AUTOSAR XML (schema 00048)
package /StartApplication/StartApplication_swc/DataTypes
  33 x impl type:
    EnumMEM_BlockStateType: compu {0=MEM_STATE_UNKNOWN, 1=MEM_STATE_WRITE_PENDING, 2=MEM_STATE_WRITE_FINISHED, 3=MEM_STATE_READ_PENDING, 4=MEM_STATE_READ_FINISHED, 5=MEM_STATE_WRITE_FAILED, 6=MEM_STATE_READ_FAILED}, range raw 0..6, implementation-data-type=uint8
    EnumNM_ApplStateType: compu {0=NM_APPL_STATE_FULL_COMM_EXTERN, 1=NM_APPL_STATE_FULL_COMM_INTERN, 2=NM_APPL_STATE_NO_COMM_EXTERN}, range raw 0..2, implementation-data-type=uint8
    NvM_ServiceIdType: compu {6=NVM_READ_BLOCK, 7=NVM_WRITE_BLOCK, 8=NVM_RESTORE_BLOCK_DEFAULTS, 9=NVM_ERASE_BLOCK, 11=NVM_INVALIDATE_NV_BLOCK, 12=NVM_READ_ALL}, range raw 0..12, implementation-data-type=uint8
    NvM_RequestResultType: compu {0=NVM_REQ_OK, 1=NVM_REQ_NOT_OK, 2=NVM_REQ_PENDING, 3=NVM_REQ_INTEGRITY_FAILED, 4=NVM_REQ_BLOCK_SKIPPED, 5=NVM_REQ_NV_INVALIDATED, 6=NVM_REQ_CANCELED, 7=NVM_REQ_REDUNDANCY_FAILED, 8=NVM_REQ_RESTORED_FROM_ROM}, range raw 0..8, implementation-data-type=uint8
    Dem_EventStatusType: compu {0=DEM_EVENT_STATUS_PASSED, 1=DEM_EVENT_STATUS_FAILED, 2=DEM_EVENT_STATUS_PREPASSED, 3=DEM_EVENT_STATUS_PREFAILED, 4=DEM_EVENT_STATUS_FDC_THRESHOLD_REACHED}, range raw 0..4, implementation-data-type=uint8
    Dem_OperationCycleStateType: compu {0=DEM_CYCLE_STATE_START, 1=DEM_CYCLE_STATE_END}, range raw 0..1, implementation-data-type=uint8
    Dcm_Data2ByteType: category=ARRAY, sw-calibration-access=READ-ONLY
      element Dcm_Data2ByteTypeElement: array-size=2, array-size-semantics=FIXED-SIZE, implementation-data-type=uint8
    Dcm_NegativeResponseCodeType:
      compu {0=DCM_E_POSITIVERESPONSE, 16=DCM_E_GENERALREJECT, 17=DCM_E_SERVICENOTSUPPORTED, 18=DCM_E_SUBFUNCTIONNOTSUPPORTED, 19=DCM_E_INCORRECTMESSAGELENGTHORINVALIDFORMAT, 20=DCM_E_RESPONSETOOLONG, 33=DCM_E_BUSYREPEATREQUEST, 34=DCM_E_CONDITIONSNOTCORRECT, 36=DCM_E_REQUESTSEQUENCEERROR, 37=DCM_E_NORESPONSEFROMSUBNETCOMPONENT, 38=DCM_E_FAILUREPREVENTSEXECUTIONOFREQUESTEDACTION, 49=DCM_E_REQUESTOUTOFRANGE, 51=DCM_E_SECURITYACCESSDENIED, 53=DCM_E_INVALIDKEY, 54=DCM_E_EXCEEDNUMBEROFATTEMPTS, 55=DCM_E_REQUIREDTIMEDELAYNOTEXPIRED, 112=DCM_E_UPLOADDOWNLOADNOTACCEPTED, 113=DCM_E_TRANSFERDATASUSPENDED, 114=DCM_E_GENERALPROGRAMMINGFAILURE, 115=DCM_E_WRONGBLOCKSEQUENCECOUNTER, 120=DCM_E_REQUESTCORRECTLYRECEIVEDRESPONSEPENDING, 126=DCM_E_SUBFUNCTIONNOTSUPPORTEDINACTIVESESSION, 127=DCM_E_SERVICENOTSUPPORTEDINACTIVESESSION, 129=DCM_E_RPMTOOHIGH, 130=DCM_E_RPMTOOLOW, 131=DCM_E_ENGINEISRUNNING, 132=DCM_E_ENGINEISNOTRUNNING, 133=DCM_E_ENGINERUNTIMETOOLOW, 134=DCM_E_TEMPERATURETOOHIGH, 135=DCM_E_TEMPERATURETOOLOW, 136=DCM_E_VEHICLESPEEDTOOHIGH, 137=DCM_E_VEHICLESPEEDTOOLOW, 138=DCM_E_THROTTLE_PEDALTOOHIGH, 139=DCM_E_THROTTLE_PEDALTOOLOW, 140=DCM_E_TRANSMISSIONRANGENOTINNEUTRAL, 141=DCM_E_TRANSMISSIONRANGENOTINGEAR, 143=DCM_E_BRAKESWITCH_NOTCLOSED, 144=DCM_E_SHIFTERLEVERNOTINPARK, 145=DCM_E_TORQUECONVERTERCLUTCHLOCKED, 146=DCM_E_VOLTAGETOOHIGH, 147=DCM_E_VOLTAGETOOLOW}
      range raw 0..147
      implementation-data-type=uint8
    DataArray_Type_2: category=ARRAY, sw-calibration-access=READ-ONLY
      element DataArray_Type_2Element: array-size=2, array-size-semantics=FIXED-SIZE, implementation-data-type=uint8
    WdgM_CheckpointIdType: implementation-data-type=uint16
    freshnessValueType: category=ARRAY, sw-calibration-access=READ-ONLY
      element freshnessValueTypeElement: array-size=8, array-size-semantics=FIXED-SIZE, implementation-data-type=uint8
    Csm_KeyDataType_StartApplication_CsmKey: category=ARRAY, sw-calibration-access=READ-ONLY
      element Csm_KeyDataType_StartApplication_CsmKeyElement: array-size=16, array-size-semantics=FIXED-SIZE, implementation-data-type=uint8
    ComM_ModeType: compu {0=COMM_NO_COMMUNICATION, 1=COMM_SILENT_COMMUNICATION, 2=COMM_FULL_COMMUNICATION}, range raw 0..3, implementation-data-type=uint8
    IdtUint8Array_508: category=ARRAY, sw-calibration-access=READ-ONLY
      element IdtUint8Array_508Element: array-size=508, array-size-semantics=FIXED-SIZE, implementation-data-type=uint8
    DtLargeDataControlCommunicationDataElementType: category=STRUCTURE
      element Value: implementation-data-type=IdtUint8Array_508
      element Length: implementation-data-type=uint16
    Csm_DecryptDataType_CsmPrimitives_AES_DecryptElement: category=ARRAY, sw-calibration-access=READ-ONLY
      element Csm_DecryptDataType_CsmPrimitives_AES_DecryptElementElement: array-size=1024, array-size-semantics=FIXED-SIZE, implementation-data-type=uint8
    Csm_DecryptResultType_CsmPrimitives_AES_DecryptElement: category=ARRAY, sw-calibration-access=READ-ONLY
      element Csm_DecryptResultType_CsmPrimitives_AES_DecryptElementElement: array-size=1024, array-size-semantics=FIXED-SIZE, implementation-data-type=uint8
    Csm_EncryptDataType_CsmPrimitives_AES_EncryptElement: category=ARRAY, sw-calibration-access=READ-ONLY
      element Csm_EncryptDataType_CsmPrimitives_AES_EncryptElementElement: array-size=1024, array-size-semantics=FIXED-SIZE, implementation-data-type=uint8
    Csm_EncryptResultType_CsmPrimitives_AES_EncryptElement: category=ARRAY, sw-calibration-access=READ-ONLY
      element Csm_EncryptResultType_CsmPrimitives_AES_EncryptElementElement: array-size=1024, array-size-semantics=FIXED-SIZE, implementation-data-type=uint8
    Csm_MacGenerateDataType_CsmPrimitives_MAC_GenerateElement: category=ARRAY, sw-calibration-access=READ-ONLY
      element Csm_MacGenerateDataType_CsmPrimitives_MAC_GenerateElementElement: array-size=1024, array-size-semantics=FIXED-SIZE, implementation-data-type=uint8
    Csm_MacGenerateResultType_CsmPrimitives_MAC_GenerateElement: category=ARRAY, sw-calibration-access=READ-ONLY
      element Csm_MacGenerateResultType_CsmPrimitives_MAC_GenerateElementElement: array-size=8, array-size-semantics=FIXED-SIZE, implementation-data-type=uint8
    Csm_MacVerifyDataType_CsmPrimitives_MAC_VerifyElement: category=ARRAY, sw-calibration-access=READ-ONLY
      element Csm_MacVerifyDataType_CsmPrimitives_MAC_VerifyElementElement: array-size=1024, array-size-semantics=FIXED-SIZE, implementation-data-type=uint8
    Csm_MacVerifyCompareType_CsmPrimitives_MAC_VerifyElement: category=ARRAY, sw-calibration-access=READ-ONLY
      element Csm_MacVerifyCompareType_CsmPrimitives_MAC_VerifyElementElement: array-size=1, array-size-semantics=FIXED-SIZE, implementation-data-type=uint8
    Crypto_VerifyResultType: compu {0=CRYPTO_E_VER_OK, 1=CRYPTO_E_VER_NOT_OK}, range raw 0..1, implementation-data-type=uint8
    Csm_KeyDataType_StartApplication_CsmKey_MAC: category=ARRAY, sw-calibration-access=READ-ONLY
      element Csm_KeyDataType_StartApplication_CsmKey_MACElement: array-size=16, array-size-semantics=FIXED-SIZE, implementation-data-type=uint8
    Csm_KeyDataType_StartApplication_CsmKey_Dec: category=ARRAY, sw-calibration-access=READ-ONLY
      element Csm_KeyDataType_StartApplication_CsmKey_DecElement: array-size=16, array-size-semantics=FIXED-SIZE, implementation-data-type=uint8
    Csm_KeyDataType_StartApplication_CsmKey_Enc: category=ARRAY, sw-calibration-access=READ-ONLY
      element Csm_KeyDataType_StartApplication_CsmKey_EncElement: array-size=16, array-size-semantics=FIXED-SIZE, implementation-data-type=uint8
    IdtLargeDataControlCommunicationInfo: category=STRUCTURE
      element Data: implementation-data-type=IdtUint8Array_508
      element Length: implementation-data-type=uint16
      element NewDataFlag: implementation-data-type=boolean
    DtInterCoreSlaveDataElementType: category=STRUCTURE
      element CoreID: implementation-data-type=uint8
      element DataValue: implementation-data-type=uint8
    EnumLastReceivedRxValueType: compu {0=STARTAPPLICATIONETH_LAST_RX_VALUE_CTRL, 1=STARTAPPLICATIONETH_LAST_RX_VALUE_DATA}, range raw 1, implementation-data-type=uint8
    DtEthernetCommunicationDataElementType: category=STRUCTURE
      element Value: implementation-data-type=IdtUint8Array_508
      element Length: implementation-data-type=uint16
    IdtEthernetCommunicationInfo: category=STRUCTURE
      element Data: implementation-data-type=IdtUint8Array_508
      element Length: implementation-data-type=uint16
      element NewDataFlag: implementation-data-type=boolean
    EnumActiveComponentType:
      compu {0=STARTAPPLICATION_ACTIVE_COMPONENT_COM_RXTX, 1=STARTAPPLICATION_ACTIVE_COMPONENT_MEM, 2=STARTAPPLICATION_ACTIVE_COMPONENT_DIAG, 3=STARTAPPLICATION_ACTIVE_COMPONENT_COM_TXONLY, 4=STARTAPPLICATION_ACTIVE_COMPONENT_WDG, 5=STARTAPPLICATION_ACTIVE_COMPONENT_XCP, 7=STARTAPPLICATION_ACTIVE_COMPONENT_MULTICORE, 9=STARTAPPLICATION_ACTIVE_COMPONENT_NM, 11=STARTAPPLICATION_ACTIVE_COMPONENT_ETH, 13=STARTAPPLICATION_ACTIVE_COMPONENT_SECURITY, 255=STARTAPPLICATION_ACTIVE_COMPONENT_INVALID}
      range raw 0..255
      implementation-data-type=uint8
package /StartApplication/StartApplication_swc/Interfaces
  5 x sender receiver interface:
    PiGeneric
      data DeGeneric: type=uint8
    PiSig_StartAppl_LinData_Tx_oFrame_LinTr_MyECU_oLIN00_d383dc6b_Tx
      data DeSig_StartAppl_LinData_Tx_oFrame_LinTr_MyECU_oLIN00_d383dc6b_Tx: type=uint8
    PiSignal_MyECU_SecOC_Rx1_omsg_SecOC_MyECU_Rx_oCAN_985386a6_Rx
      data DeSignal_MyECU_SecOC_Rx1_omsg_SecOC_MyECU_Rx_oCAN_985386a6_Rx: type=uint8
    PiSignal_MyECU_SecOC_Tx1_omsg_SecOC_MyECU_Tx_oCAN_fe3fbdd2_Tx
      data DeSignal_MyECU_SecOC_Tx1_omsg_SecOC_MyECU_Tx_oCAN_fe3fbdd2_Tx: type=uint8
    PiSig_StartAppl_LinData_Rx_oFrame_LinTr_Slave1_oLIN00_149fe319_Rx
      data DeSig_StartAppl_LinData_Rx_oFrame_LinTr_Slave1_oLIN00_149fe319_Rx: type=uint8
  15 x client server interface, all with is-service=true, service-kind=VENDOR-SPECIFIC:
    PiUR_CN_LIN00_0a7bdc9c
      4 x operation:
        GetCurrentComMode: possible-error=PiUR_CN_LIN00_0a7bdc9c/E_NOT_OK
          arg ComMode: type=ComM_ModeType, direction=OUT
        GetMaxComMode: possible-error=PiUR_CN_LIN00_0a7bdc9c/E_NOT_OK
          arg ComMode: type=ComM_ModeType, direction=OUT
        GetRequestedComMode: possible-error=PiUR_CN_LIN00_0a7bdc9c/E_NOT_OK
          arg ComMode: type=ComM_ModeType, direction=OUT
        RequestComMode: possible-error=[PiUR_CN_LIN00_0a7bdc9c/E_NOT_OK, PiUR_CN_LIN00_0a7bdc9c/E_MODE_LIMITATION]
          arg ComMode: type=ComM_ModeType, direction=IN
      error E_NOT_OK: error-code=1
      error E_MODE_LIMITATION: error-code=2
    PiUR_CN_CAN_52ce3533
      4 x operation:
        GetCurrentComMode: possible-error=PiUR_CN_CAN_52ce3533/E_NOT_OK
          arg ComMode: type=ComM_ModeType, direction=OUT
        GetMaxComMode: possible-error=PiUR_CN_CAN_52ce3533/E_NOT_OK
          arg ComMode: type=ComM_ModeType, direction=OUT
        GetRequestedComMode: possible-error=PiUR_CN_CAN_52ce3533/E_NOT_OK
          arg ComMode: type=ComM_ModeType, direction=OUT
        RequestComMode: possible-error=[PiUR_CN_CAN_52ce3533/E_NOT_OK, PiUR_CN_CAN_52ce3533/E_MODE_LIMITATION]
          arg ComMode: type=ComM_ModeType, direction=IN
      error E_NOT_OK: error-code=1
      error E_MODE_LIMITATION: error-code=2
    PiUR_MyECU_EEI_V10_NM_507fc7ae
      4 x operation:
        GetCurrentComMode: possible-error=PiUR_MyECU_EEI_V10_NM_507fc7ae/E_NOT_OK
          arg ComMode: type=ComM_ModeType, direction=OUT
        GetMaxComMode: possible-error=PiUR_MyECU_EEI_V10_NM_507fc7ae/E_NOT_OK
          arg ComMode: type=ComM_ModeType, direction=OUT
        GetRequestedComMode: possible-error=PiUR_MyECU_EEI_V10_NM_507fc7ae/E_NOT_OK
          arg ComMode: type=ComM_ModeType, direction=OUT
        RequestComMode: possible-error=[PiUR_MyECU_EEI_V10_NM_507fc7ae/E_NOT_OK, PiUR_MyECU_EEI_V10_NM_507fc7ae/E_MODE_LIMITATION]
          arg ComMode: type=ComM_ModeType, direction=IN
      error E_NOT_OK: error-code=1
      error E_MODE_LIMITATION: error-code=2
    PiUR_MyECU_EEI_U_2cc5e3dc
      4 x operation:
        GetCurrentComMode: possible-error=PiUR_MyECU_EEI_U_2cc5e3dc/E_NOT_OK
          arg ComMode: type=ComM_ModeType, direction=OUT
        GetMaxComMode: possible-error=PiUR_MyECU_EEI_U_2cc5e3dc/E_NOT_OK
          arg ComMode: type=ComM_ModeType, direction=OUT
        GetRequestedComMode: possible-error=PiUR_MyECU_EEI_U_2cc5e3dc/E_NOT_OK
          arg ComMode: type=ComM_ModeType, direction=OUT
        RequestComMode: possible-error=[PiUR_MyECU_EEI_U_2cc5e3dc/E_NOT_OK, PiUR_MyECU_EEI_U_2cc5e3dc/E_MODE_LIMITATION]
          arg ComMode: type=ComM_ModeType, direction=IN
      error E_NOT_OK: error-code=1
      error E_MODE_LIMITATION: error-code=2
    PiPS_StartApplication_NvMBlock1
      operation WriteBlock: possible-error=PiPS_StartApplication_NvMBlock1/E_NOT_OK
        arg SrcPtr: type=dtRef_const_VOID, direction=IN
      operation ReadBlock: possible-error=PiPS_StartApplication_NvMBlock1/E_NOT_OK
        arg DstPtr: type=dtRef_VOID, direction=IN
      error E_NOT_OK: error-code=1
    PiNvM_RpNotifyJobEnd_StartApplication_NvMBlock1
      operation JobFinished
        arg ServiceId: type=NvM_ServiceIdType, direction=IN
        arg JobResult: type=NvM_RequestResultType, direction=IN
    PiPS_StartApplication_NvMBlock2
      operation WriteBlock: possible-error=PiPS_StartApplication_NvMBlock2/E_NOT_OK
        arg SrcPtr: type=dtRef_const_VOID, direction=IN
      operation ReadBlock: possible-error=PiPS_StartApplication_NvMBlock2/E_NOT_OK
        arg DstPtr: type=dtRef_VOID, direction=IN
      error E_NOT_OK: error-code=1
    PiNvM_RpNotifyJobEnd_StartApplication_NvMBlock2
      operation JobFinished
        arg ServiceId: type=NvM_ServiceIdType, direction=IN
        arg JobResult: type=NvM_RequestResultType, direction=IN
    PiDiagnosticMonitor_DEM_EVENT_StartApplication
      operation SetEventStatus: possible-error=PiDiagnosticMonitor_DEM_EVENT_StartApplication/E_NOT_OK
        arg EventStatus: type=Dem_EventStatusType, direction=IN
      operation ResetEventStatus: possible-error=PiDiagnosticMonitor_DEM_EVENT_StartApplication/E_NOT_OK
      error E_NOT_OK: error-code=1
    PiDemOpCycle_PowerCycle
      operation SetOperationCycleState: possible-error=PiDemOpCycle_PowerCycle/E_NOT_OK
        arg CycleState: type=Dem_OperationCycleStateType, direction=IN
      error E_NOT_OK: error-code=1
    PiDcmDataService_DID_StartApplication
      operation WriteData
        arg Data: type=Dcm_Data2ByteType, direction=IN
        arg ErrorCode: type=Dcm_NegativeResponseCodeType, direction=OUT
      operation ReadData
        arg Data: type=Dcm_Data2ByteType, direction=OUT
      operation ConditionCheckRead
        arg ErrorCode: type=Dcm_NegativeResponseCodeType, direction=OUT
    PiDemDataService_DemDataElementClass_StartApplication
      operation ReadData
        arg Data: type=DataArray_Type_2, direction=OUT
    PiAliveWdgMSupervisedEntity_StartApplication
      operation CheckpointReached: possible-error=PiAliveWdgMSupervisedEntity_StartApplication/E_NOT_OK
        arg checkpointId: type=WdgM_CheckpointIdType, direction=IN
      error E_NOT_OK: error-code=1
    PiCsmKeyManagement_StartApplication_CsmKey
      operation KeyElementSet: possible-error=[PiCsmKeyManagement_StartApplication_CsmKey/E_NOT_OK, PiCsmKeyManagement_StartApplication_CsmKey/CSM_E_BUSY, PiCsmKeyManagement_StartApplication_CsmKey/CSM_E_SMALL_BUFFER, PiCsmKeyManagement_StartApplication_CsmKey/CSM_E_KEY_WRITE_FAIL, PiCsmKeyManagement_StartApplication_CsmKey/CSM_E_KEY_NOT_AVAILABLE, PiCsmKeyManagement_StartApplication_CsmKey/CSM_E_KEY_SIZE_MISMATCH]
        arg keyElementId: type=uint32, direction=IN
        arg keyPtr: type=Csm_KeyDataType_StartApplication_CsmKey, direction=IN, server-argument-impl-policy=USE-ARRAY-BASE-TYPE
        arg keyLength: type=uint32, direction=IN
      operation KeySetValid: possible-error=[PiCsmKeyManagement_StartApplication_CsmKey/E_NOT_OK, PiCsmKeyManagement_StartApplication_CsmKey/CSM_E_BUSY]
      6 x error:
        E_NOT_OK: error-code=1
        CSM_E_BUSY: error-code=2
        CSM_E_SMALL_BUFFER: error-code=3
        CSM_E_KEY_WRITE_FAIL: error-code=7
        CSM_E_KEY_NOT_AVAILABLE: error-code=8
        CSM_E_KEY_SIZE_MISMATCH: error-code=10
    PiFreshnessManagement
      operation GetRxFreshness: possible-error=[E_OK, PiFreshnessManagement/E_NOT_OK, E_BUSY]
        6 x arg:
          freshnessValueId: type=uint16, direction=IN
          truncatedFreshnessValue: type=freshnessValueType, direction=IN
          truncatedFreshnessValueLength: type=uint32, direction=IN
          authVerifyAttempts: type=uint16, direction=IN
          freshnessValue: type=freshnessValueType, direction=OUT
          freshnessValueLength: type=uint32, direction=INOUT
      operation GetTxFreshness: possible-error=[E_OK, PiFreshnessManagement/E_NOT_OK, E_BUSY]
        arg freshnessValueId: type=uint16, direction=IN
        arg freshnessValue: type=freshnessValueType, direction=OUT
        arg freshnessValueLength: type=uint32, direction=INOUT
      error E_OK: error-code=0
      error E_NOT_OK: error-code=1
      error E_BUSY: error-code=2
  sender receiver interface PiLargeDataControlCommunication
    data DeLargeDataControlCommunication: sw-impl-policy=QUEUED, type=DtLargeDataControlCommunicationDataElementType
  7 x client server interface, all with is-service=true, service-kind=VENDOR-SPECIFIC:
    PiStartApplication_ECB_AES_Decrypt
      operation Decrypt: possible-error=[PiStartApplication_ECB_AES_Decrypt/E_NOT_OK, PiStartApplication_ECB_AES_Decrypt/CSM_E_BUSY, PiStartApplication_ECB_AES_Decrypt/CSM_E_SMALL_BUFFER, PiStartApplication_ECB_AES_Decrypt/CSM_E_KEY_NOT_VALID, PiStartApplication_ECB_AES_Decrypt/CSM_E_KEY_SIZE_MISMATCH, PiStartApplication_ECB_AES_Decrypt/CSM_E_KEY_EMPTY]
        4 x arg:
          dataBuffer: type=Csm_DecryptDataType_CsmPrimitives_AES_DecryptElement, direction=IN
          dataLength: type=uint32, direction=IN
          resultBuffer: type=Csm_DecryptResultType_CsmPrimitives_AES_DecryptElement, direction=OUT
          resultLength: type=uint32, direction=INOUT
      6 x error:
        E_NOT_OK: error-code=1
        CSM_E_BUSY: error-code=2
        CSM_E_SMALL_BUFFER: error-code=3
        CSM_E_KEY_NOT_VALID: error-code=9
        CSM_E_KEY_SIZE_MISMATCH: error-code=10
        CSM_E_KEY_EMPTY: error-code=13
    PiStartApplication_ECB_AES_Encrypt
      operation Encrypt: possible-error=[PiStartApplication_ECB_AES_Encrypt/E_NOT_OK, PiStartApplication_ECB_AES_Encrypt/CSM_E_BUSY, PiStartApplication_ECB_AES_Encrypt/CSM_E_SMALL_BUFFER, PiStartApplication_ECB_AES_Encrypt/CSM_E_KEY_NOT_VALID, PiStartApplication_ECB_AES_Encrypt/CSM_E_KEY_SIZE_MISMATCH, PiStartApplication_ECB_AES_Encrypt/CSM_E_KEY_EMPTY]
        4 x arg:
          dataBuffer: type=Csm_EncryptDataType_CsmPrimitives_AES_EncryptElement, direction=IN
          dataLength: type=uint32, direction=IN
          resultBuffer: type=Csm_EncryptResultType_CsmPrimitives_AES_EncryptElement, direction=OUT
          resultLength: type=uint32, direction=INOUT
      6 x error:
        E_NOT_OK: error-code=1
        CSM_E_BUSY: error-code=2
        CSM_E_SMALL_BUFFER: error-code=3
        CSM_E_KEY_NOT_VALID: error-code=9
        CSM_E_KEY_SIZE_MISMATCH: error-code=10
        CSM_E_KEY_EMPTY: error-code=13
    PiStartApplication_MAC_Generate
      operation MacGenerate: possible-error=[PiStartApplication_MAC_Generate/E_NOT_OK, PiStartApplication_MAC_Generate/CSM_E_BUSY, PiStartApplication_MAC_Generate/CSM_E_SMALL_BUFFER]
        4 x arg:
          dataBuffer: type=Csm_MacGenerateDataType_CsmPrimitives_MAC_GenerateElement, direction=IN
          dataLength: type=uint32, direction=IN
          resultBuffer: type=Csm_MacGenerateResultType_CsmPrimitives_MAC_GenerateElement, direction=OUT
          resultLength: type=uint32, direction=INOUT
      error E_NOT_OK: error-code=1
      error CSM_E_BUSY: error-code=2
      error CSM_E_SMALL_BUFFER: error-code=3
    PiStartApplication_MAC_Verify
      operation MacVerify: possible-error=[PiStartApplication_MAC_Verify/E_NOT_OK, PiStartApplication_MAC_Verify/CSM_E_BUSY, PiStartApplication_MAC_Verify/CSM_E_SMALL_BUFFER]
        5 x arg:
          dataBuffer: type=Csm_MacVerifyDataType_CsmPrimitives_MAC_VerifyElement, direction=IN
          dataLength: type=uint32, direction=IN
          compareBuffer: type=Csm_MacVerifyCompareType_CsmPrimitives_MAC_VerifyElement, direction=IN
          compareLength: type=uint32, direction=IN
          verifyResult: type=Crypto_VerifyResultType, direction=OUT
      error E_NOT_OK: error-code=1
      error CSM_E_BUSY: error-code=2
      error CSM_E_SMALL_BUFFER: error-code=3
    PiStartApplication_CsmKey_MAC
      operation KeySetValid: possible-error=[PiStartApplication_CsmKey_MAC/E_NOT_OK, PiStartApplication_CsmKey_MAC/CSM_E_BUSY]
      operation KeyElementSet: possible-error=[PiStartApplication_CsmKey_MAC/E_NOT_OK, PiStartApplication_CsmKey_MAC/CSM_E_BUSY, PiStartApplication_CsmKey_MAC/CSM_E_KEY_WRITE_FAIL, PiStartApplication_CsmKey_MAC/CSM_E_KEY_NOT_AVAILABLE, PiStartApplication_CsmKey_MAC/CSM_E_KEY_SIZE_MISMATCH]
        arg keyElementId: type=uint32, direction=IN
        arg keyPtr: type=Csm_KeyDataType_StartApplication_CsmKey_MAC, direction=IN
        arg keyLength: type=uint32, direction=IN
      operation KeyElementGet: possible-error=[PiStartApplication_CsmKey_MAC/E_NOT_OK, PiStartApplication_CsmKey_MAC/CSM_E_BUSY, PiStartApplication_CsmKey_MAC/CSM_E_SMALL_BUFFER, PiStartApplication_CsmKey_MAC/CSM_E_KEY_READ_FAIL, PiStartApplication_CsmKey_MAC/CSM_E_KEY_NOT_AVAILABLE, PiStartApplication_CsmKey_MAC/CSM_E_KEY_EMPTY]
        arg keyElementId: type=uint32, direction=IN
        arg keyPtr: type=Csm_KeyDataType_StartApplication_CsmKey_MAC, direction=OUT
        arg keyLength: type=uint32, direction=OUT
      8 x error:
        E_NOT_OK: error-code=1
        CSM_E_BUSY: error-code=2
        CSM_E_KEY_WRITE_FAIL: error-code=7
        CSM_E_KEY_NOT_AVAILABLE: error-code=8
        CSM_E_KEY_SIZE_MISMATCH: error-code=10
        CSM_E_SMALL_BUFFER: error-code=3
        CSM_E_KEY_READ_FAIL: error-code=6
        CSM_E_KEY_EMPTY: error-code=13
    PiStartApplication_CsmKey_Dec
      operation KeySetValid: possible-error=[PiStartApplication_CsmKey_Dec/E_NOT_OK, PiStartApplication_CsmKey_Dec/CSM_E_BUSY]
      operation KeyElementSet: possible-error=[PiStartApplication_CsmKey_Dec/E_NOT_OK, PiStartApplication_CsmKey_Dec/CSM_E_BUSY, PiStartApplication_CsmKey_Dec/CSM_E_KEY_WRITE_FAIL, PiStartApplication_CsmKey_Dec/CSM_E_KEY_NOT_AVAILABLE, PiStartApplication_CsmKey_Dec/CSM_E_KEY_SIZE_MISMATCH]
        arg keyElementId: type=uint32, direction=IN
        arg keyPtr: type=Csm_KeyDataType_StartApplication_CsmKey_Dec, direction=IN
        arg keyLength: type=uint32, direction=IN
      operation KeyElementGet: possible-error=[PiStartApplication_CsmKey_Dec/E_NOT_OK, PiStartApplication_CsmKey_Dec/CSM_E_BUSY, PiStartApplication_CsmKey_Dec/CSM_E_SMALL_BUFFER, PiStartApplication_CsmKey_Dec/CSM_E_KEY_READ_FAIL, PiStartApplication_CsmKey_Dec/CSM_E_KEY_NOT_AVAILABLE]
        arg keyElementId: type=uint32, direction=IN
        arg keyPtr: type=Csm_KeyDataType_StartApplication_CsmKey_Dec, direction=OUT
        arg keyLength: type=uint32, direction=OUT
      7 x error:
        E_NOT_OK: error-code=1
        CSM_E_BUSY: error-code=2
        CSM_E_KEY_WRITE_FAIL: error-code=7
        CSM_E_KEY_NOT_AVAILABLE: error-code=8
        CSM_E_KEY_SIZE_MISMATCH: error-code=10
        CSM_E_SMALL_BUFFER: error-code=3
        CSM_E_KEY_READ_FAIL: error-code=6
    PiStartApplication_CsmKey_Enc
      operation KeySetValid: possible-error=[PiStartApplication_CsmKey_Enc/E_NOT_OK, PiStartApplication_CsmKey_Enc/CSM_E_BUSY]
      operation KeyElementSet: possible-error=[PiStartApplication_CsmKey_Enc/E_NOT_OK, PiStartApplication_CsmKey_Enc/CSM_E_BUSY, PiStartApplication_CsmKey_Enc/CSM_E_KEY_WRITE_FAIL, PiStartApplication_CsmKey_Enc/CSM_E_KEY_NOT_AVAILABLE, PiStartApplication_CsmKey_Enc/CSM_E_KEY_SIZE_MISMATCH]
        arg keyElementId: type=uint32, direction=IN
        arg keyPtr: type=Csm_KeyDataType_StartApplication_CsmKey_Enc, direction=IN
        arg keyLength: type=uint32, direction=IN
      operation KeyElementGet: possible-error=[PiStartApplication_CsmKey_Enc/E_NOT_OK, PiStartApplication_CsmKey_Enc/CSM_E_BUSY, PiStartApplication_CsmKey_Enc/CSM_E_SMALL_BUFFER, PiStartApplication_CsmKey_Enc/CSM_E_KEY_READ_FAIL, PiStartApplication_CsmKey_Enc/CSM_E_KEY_NOT_AVAILABLE, PiStartApplication_CsmKey_Enc/CSM_E_KEY_EMPTY]
        arg keyElementId: type=uint32, direction=IN
        arg keyPtr: type=Csm_KeyDataType_StartApplication_CsmKey_Enc, direction=OUT
        arg keyLength: type=uint32, direction=OUT
      8 x error:
        E_NOT_OK: error-code=1
        CSM_E_BUSY: error-code=2
        CSM_E_KEY_WRITE_FAIL: error-code=7
        CSM_E_KEY_NOT_AVAILABLE: error-code=8
        CSM_E_KEY_SIZE_MISMATCH: error-code=10
        CSM_E_SMALL_BUFFER: error-code=3
        CSM_E_KEY_READ_FAIL: error-code=6
        CSM_E_KEY_EMPTY: error-code=13
  5 x sender receiver interface:
    PiSignal_StartAppl_TxData_MyECU_omsg_StartAppl_Tx_MyECU_oCAN_8c58228b_Tx
      data DeSignal_StartAppl_TxData_MyECU_omsg_StartAppl_Tx_MyECU_oCAN_8c58228b_Tx: type=uint8
    PiSignal_StartAppl_RxData_MyECU_omsg_StartAppl_Rx_MyECU_oCAN_315f9453_Rx
      data DeSignal_StartAppl_RxData_MyECU_omsg_StartAppl_Rx_MyECU_oCAN_315f9453_Rx: type=uint8
    PiStartApplication_InterCoreMaster
      data DeInterCoreMaster: type=uint8
    PiStartApplication_InterCoreSlave
      data DeInterCoreSlave: type=DtInterCoreSlaveDataElementType
    PiEthernetCommunication
      data DeEthernetCommunication: sw-impl-policy=QUEUED, type=DtEthernetCommunicationDataElementType
package /StartApplication/StartApplication_swc/ComponentTypes
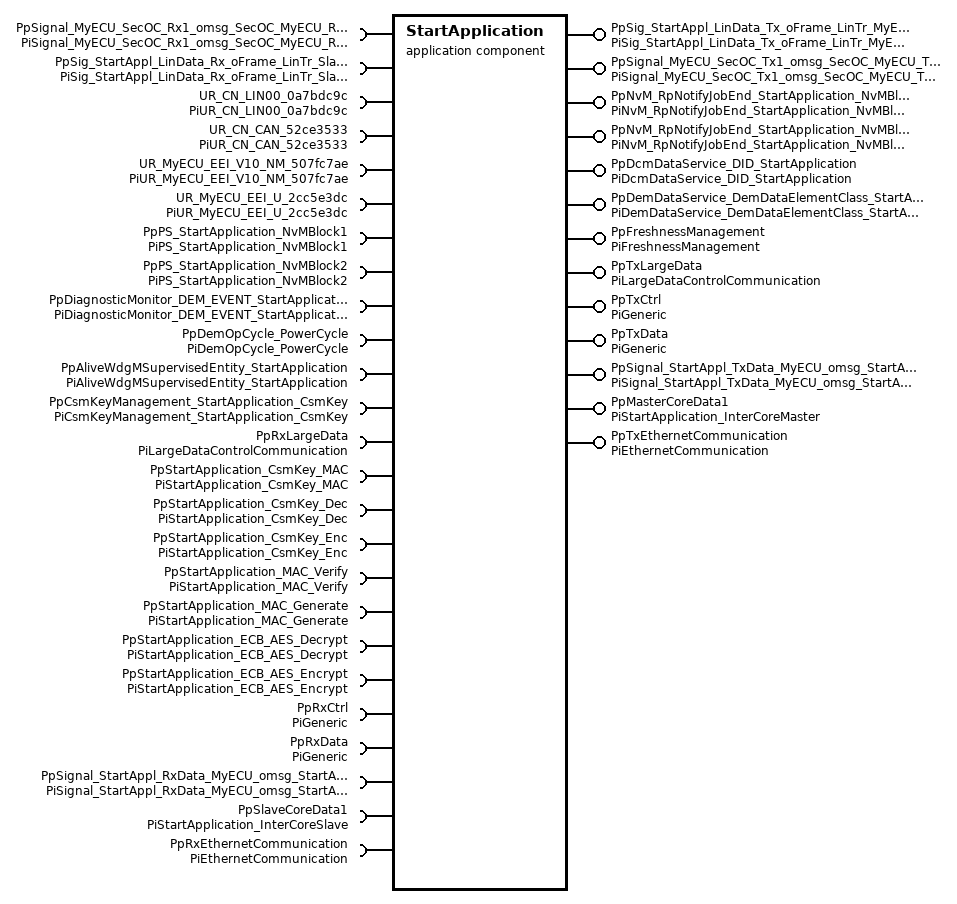
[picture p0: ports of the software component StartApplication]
  application sw component type StartApplication
    provide port PpSig_StartAppl_LinData_Tx_oFrame_LinTr_MyECU_oLIN00_d383dc6b_Tx: nonqueued-sender-com-spec{data-element=DeSig_StartAppl_LinData_Tx_oFrame_LinTr_MyECU_oLIN00_d383dc6b_Tx, init-value=0}, provided-interface=PiSig_StartAppl_LinData_Tx_oFrame_LinTr_MyECU_oLIN00_d383dc6b_Tx
    require port PpSignal_MyECU_SecOC_Rx1_omsg_SecOC_MyECU_Rx_oCAN_985386a6_Rx: nonqueued-receiver-com-spec{data-element=DeSignal_MyECU_SecOC_Rx1_omsg_SecOC_MyECU_Rx_oCAN_985386a6_Rx, handle-out-of-range-status=SILENT, init-value=0}, required-interface=PiSignal_MyECU_SecOC_Rx1_omsg_SecOC_MyECU_Rx_oCAN_985386a6_Rx
    provide port PpSignal_MyECU_SecOC_Tx1_omsg_SecOC_MyECU_Tx_oCAN_fe3fbdd2_Tx: nonqueued-sender-com-spec{data-element=DeSignal_MyECU_SecOC_Tx1_omsg_SecOC_MyECU_Tx_oCAN_fe3fbdd2_Tx, init-value=0}, provided-interface=PiSignal_MyECU_SecOC_Tx1_omsg_SecOC_MyECU_Tx_oCAN_fe3fbdd2_Tx
    5 x require port:
      PpSig_StartAppl_LinData_Rx_oFrame_LinTr_Slave1_oLIN00_149fe319_Rx: nonqueued-receiver-com-spec{data-element=DeSig_StartAppl_LinData_Rx_oFrame_LinTr_Slave1_oLIN00_149fe319_Rx, handle-out-of-range-status=SILENT, init-value=0}, required-interface=PiSig_StartAppl_LinData_Rx_oFrame_LinTr_Slave1_oLIN00_149fe319_Rx
      UR_CN_LIN00_0a7bdc9c: required-interface=PiUR_CN_LIN00_0a7bdc9c
      UR_CN_CAN_52ce3533: required-interface=PiUR_CN_CAN_52ce3533
      UR_MyECU_EEI_V10_NM_507fc7ae: required-interface=PiUR_MyECU_EEI_V10_NM_507fc7ae
      UR_MyECU_EEI_U_2cc5e3dc: required-interface=PiUR_MyECU_EEI_U_2cc5e3dc
    provide port PpNvM_RpNotifyJobEnd_StartApplication_NvMBlock1: provided-interface=PiNvM_RpNotifyJobEnd_StartApplication_NvMBlock1
    require port PpPS_StartApplication_NvMBlock1: required-interface=PiPS_StartApplication_NvMBlock1
    provide port PpNvM_RpNotifyJobEnd_StartApplication_NvMBlock2: provided-interface=PiNvM_RpNotifyJobEnd_StartApplication_NvMBlock2
    require port PpPS_StartApplication_NvMBlock2: required-interface=PiPS_StartApplication_NvMBlock2
    require port PpDiagnosticMonitor_DEM_EVENT_StartApplication: required-interface=PiDiagnosticMonitor_DEM_EVENT_StartApplication
    require port PpDemOpCycle_PowerCycle: required-interface=PiDemOpCycle_PowerCycle
    provide port PpDcmDataService_DID_StartApplication: provided-interface=PiDcmDataService_DID_StartApplication
    provide port PpDemDataService_DemDataElementClass_StartApplication: provided-interface=PiDemDataService_DemDataElementClass_StartApplication
    require port PpAliveWdgMSupervisedEntity_StartApplication: required-interface=PiAliveWdgMSupervisedEntity_StartApplication
    require port PpCsmKeyManagement_StartApplication_CsmKey: required-interface=PiCsmKeyManagement_StartApplication_CsmKey
    provide port PpFreshnessManagement: provided-interface=PiFreshnessManagement
    require port PpRxLargeData: nonqueued-receiver-com-spec{data-element=DeLargeDataControlCommunication, handle-out-of-range-status=SILENT}, required-interface=PiLargeDataControlCommunication
    provide port PpTxLargeData: nonqueued-sender-com-spec=DeLargeDataControlCommunication, provided-interface=PiLargeDataControlCommunication
    7 x require port:
      PpStartApplication_CsmKey_MAC: required-interface=PiStartApplication_CsmKey_MAC
      PpStartApplication_CsmKey_Dec: required-interface=PiStartApplication_CsmKey_Dec
      PpStartApplication_CsmKey_Enc: required-interface=PiStartApplication_CsmKey_Enc
      PpStartApplication_MAC_Verify: required-interface=PiStartApplication_MAC_Verify
      PpStartApplication_MAC_Generate: required-interface=PiStartApplication_MAC_Generate
      PpStartApplication_ECB_AES_Decrypt: required-interface=PiStartApplication_ECB_AES_Decrypt
      PpStartApplication_ECB_AES_Encrypt: required-interface=PiStartApplication_ECB_AES_Encrypt
    provide port PpTxCtrl: nonqueued-sender-com-spec{data-element=DeGeneric, init-value=0}, provided-interface=PiGeneric
    provide port PpTxData: nonqueued-sender-com-spec{data-element=DeGeneric, init-value=0}, provided-interface=PiGeneric
    require port PpRxCtrl: nonqueued-receiver-com-spec{data-element=DeGeneric, handle-out-of-range-status=SILENT, init-value=0}, required-interface=PiGeneric
    require port PpRxData: nonqueued-receiver-com-spec{data-element=DeGeneric, handle-out-of-range-status=SILENT, init-value=0}, required-interface=PiGeneric
    provide port PpSignal_StartAppl_TxData_MyECU_omsg_StartAppl_Tx_MyECU_oCAN_8c58228b_Tx: nonqueued-sender-com-spec{data-element=DeSignal_StartAppl_TxData_MyECU_omsg_StartAppl_Tx_MyECU_oCAN_8c58228b_Tx, init-value=0}, provided-interface=PiSignal_StartAppl_TxData_MyECU_omsg_StartAppl_Tx_MyECU_oCAN_8c58228b_Tx
    require port PpSignal_StartAppl_RxData_MyECU_omsg_StartAppl_Rx_MyECU_oCAN_315f9453_Rx: nonqueued-receiver-com-spec{data-element=DeSignal_StartAppl_RxData_MyECU_omsg_StartAppl_Rx_MyECU_oCAN_315f9453_Rx, handle-out-of-range-status=SILENT, init-value=0}, required-interface=PiSignal_StartAppl_RxData_MyECU_omsg_StartAppl_Rx_MyECU_oCAN_315f9453_Rx
    provide port PpMasterCoreData1: nonqueued-sender-com-spec{data-element=DeInterCoreMaster, init-value=0}, provided-interface=PiStartApplication_InterCoreMaster
    require port PpSlaveCoreData1: nonqueued-receiver-com-spec{data-element=DeInterCoreSlave, handle-out-of-range-status=SILENT, init-value=fields=[0, 0]}, required-interface=PiStartApplication_InterCoreSlave
    require port PpRxEthernetCommunication: nonqueued-receiver-com-spec{data-element=DeEthernetCommunication, handle-out-of-range-status=SILENT}, required-interface=PiEthernetCommunication
    provide port PpTxEthernetCommunication: nonqueued-sender-com-spec=DeEthernetCommunication, provided-interface=PiEthernetCommunication
    behavior StartApplicationInternalBehavior: handle-termination-and-restart=NO-SUPPORT
      ar-typed-per-instance-memorys:
        27 x data:
          Uptime: type=uint8
          TxCtrlSigValue: type=uint8
          TxDataSigValue: type=uint8
          SecOCTxFreshnessValue0: type=uint8
          COM_RxSigValue0: type=uint8
          COM_TxSigValue0: type=uint8
          COM_RxSigValue1: type=uint8
          COM_TxSigValue1: type=uint8
          COM_RxSigValue2: type=uint8
          COM_TxSigValue2: type=uint8
          MEM_ActiveBlock: type=uint8
          MEM_DataBuffer1: type=uint8
          MEM_DataBuffer2: type=uint8
          MEM_BlockState1: type=EnumMEM_BlockStateType
          MEM_BlockState2: type=EnumMEM_BlockStateType
          DIAG_LastRxData: type=uint8
          NM_ApplState: type=EnumNM_ApplStateType
          NM_ActiveChannelHasFullComRequest: type=uint8
          NM_BusSleepModeTimer: type=uint8
          NM_ActiveComMChannel: type=uint8
          NM_ActiveComMUsers: type=uint32
          WDG_AliveCycle: type=uint8
          WDG_AliveTimer: type=uint8
          XcpPimUpload: sw-calibration-access=READ-WRITE, type=uint16
          XcpPimDownload: sw-calibration-access=READ-WRITE, type=uint16
          ActiveComponent: type=EnumActiveComponentType
          COM_RxDataControlCommunicationBuffer: type=uint8
      4 x timing event:
        Timer_StartApplication_Cyclic1ms: start-on-event=StartApplication_Cyclic1ms, period=0.001
        Timer_StartApplication_Cyclic10ms: start-on-event=StartApplication_Cyclic10ms, period=0.01
        Timer_StartApplication_Cyclic250ms: start-on-event=StartApplication_Cyclic250ms, period=0.25
        Timer_StartApplication_Cyclic1000ms: start-on-event=StartApplication_Cyclic1000ms, period=1
      init event Timer_StartApplication_Init: start-on-event=StartApplication_Init
      8 x operation invoked event:
        OpEventStartApplication_MEM_JobFinished_StartApplication_NvMBlock1_JobFinished_PpNvM_RpNotifyJobEnd_StartApplication_NvMBlock1: start-on-event=StartApplication_MEM_JobFinished_StartApplication_NvMBlock1, operation=PpNvM_RpNotifyJobEnd_StartApplication_NvMBlock1.JobFinished
        OpEventStartApplication_MEM_JobFinished_StartApplication_NvMBlock2_JobFinished_PpNvM_RpNotifyJobEnd_StartApplication_NvMBlock2: start-on-event=StartApplication_MEM_JobFinished_StartApplication_NvMBlock2, operation=PpNvM_RpNotifyJobEnd_StartApplication_NvMBlock2.JobFinished
        OpEventStartApplication_DIAG_DcmReadData_ReadData_PpDcmDataService_DID_StartApplication: start-on-event=StartApplication_DIAG_DcmReadData, operation=PpDcmDataService_DID_StartApplication.ReadData
        OpEventStartApplication_DIAG_DcmWriteData_WriteData_PpDcmDataService_DID_StartApplication: start-on-event=StartApplication_DIAG_DcmWriteData, operation=PpDcmDataService_DID_StartApplication.WriteData
        OpEventStartApplication_DIAG_ConditionCheckRead_ConditionCheckRead_PpDcmDataService_DID_StartApplication: start-on-event=StartApplication_DIAG_ConditionCheckRead, operation=PpDcmDataService_DID_StartApplication.ConditionCheckRead
        OpEventStartApplication_DIAG_DemReadData_ReadData_PpDemDataService_DemDataElementClass_StartApplication: start-on-event=StartApplication_DIAG_DemReadData, operation=PpDemDataService_DemDataElementClass_StartApplication.ReadData
        OpEventStartApplication_SecOC_FreshnessManagement_GetRxFreshness_GetRxFreshness_PpFreshnessManagement: start-on-event=StartApplication_SecOC_FreshnessManagement_GetRxFreshness, operation=PpFreshnessManagement.GetRxFreshness
        OpEventStartApplication_SecOC_FreshnessManagement_GetTxFreshness_GetTxFreshness_PpFreshnessManagement: start-on-event=StartApplication_SecOC_FreshnessManagement_GetTxFreshness, operation=PpFreshnessManagement.GetTxFreshness
      5 x data received event:
        DataReceivedEvent_StartApplication_OnDataRec_RxLargeData_PpRxLargeData_DeLargeDataControlCommunication: start-on-event=StartApplication_OnDataRec_RxLargeData, data=PpRxLargeData.DeLargeDataControlCommunication
        DataReceivedEvent_StartApplication_OnDataRec_RxCtrl_PpRxCtrl_DeGeneric: start-on-event=StartApplication_OnDataRec_RxCtrl, data=PpRxCtrl.DeGeneric
        DataReceivedEvent_StartApplication_OnDataRec_RxData_PpRxData_DeGeneric: start-on-event=StartApplication_OnDataRec_RxData, data=PpRxData.DeGeneric
        DataReceivedEvent_StartApplication_OnDataRec_SlaveCore1_PpSlaveCoreData1_DeInterCoreSlave: start-on-event=StartApplication_OnDataRec_SlaveCore1, data=PpSlaveCoreData1.DeInterCoreSlave
        DataReceivedEvent_StartApplication_OnDataRec_EthernetCommunication_PpRxEthernetCommunication_DeEthernetCommunication: start-on-event=StartApplication_OnDataRec_EthernetCommunication, data=PpRxEthernetCommunication.DeEthernetCommunication
      explicit-inter-runnable-variables:
        data IrvOccuranceCounterDid: type=uint16, init-value=0
      port-api-options:
        enable-take-address=true, indirect-api=false, port=PpSig_StartAppl_LinData_Tx_oFrame_LinTr_MyECU_oLIN00_d383dc6b_Tx
        enable-take-address=true, indirect-api=false, port=PpSignal_MyECU_SecOC_Rx1_omsg_SecOC_MyECU_Rx_oCAN_985386a6_Rx
        enable-take-address=true, indirect-api=false, port=PpSignal_MyECU_SecOC_Tx1_omsg_SecOC_MyECU_Tx_oCAN_fe3fbdd2_Tx
        enable-take-address=true, indirect-api=false, port=PpSig_StartAppl_LinData_Rx_oFrame_LinTr_Slave1_oLIN00_149fe319_Rx
        enable-take-address=true, indirect-api=false, port=UR_CN_LIN00_0a7bdc9c
        enable-take-address=true, indirect-api=false, port=UR_CN_CAN_52ce3533
        enable-take-address=true, indirect-api=false, port=UR_MyECU_EEI_V10_NM_507fc7ae
        enable-take-address=true, indirect-api=false, port=UR_MyECU_EEI_U_2cc5e3dc
        enable-take-address=true, indirect-api=false, port=PpNvM_RpNotifyJobEnd_StartApplication_NvMBlock1
        enable-take-address=true, indirect-api=false, port=PpPS_StartApplication_NvMBlock1
        enable-take-address=true, indirect-api=false, port=PpNvM_RpNotifyJobEnd_StartApplication_NvMBlock2
        enable-take-address=true, indirect-api=false, port=PpPS_StartApplication_NvMBlock2
        enable-take-address=true, indirect-api=false, port=PpDiagnosticMonitor_DEM_EVENT_StartApplication
        enable-take-address=true, indirect-api=false, port=PpDemOpCycle_PowerCycle
        enable-take-address=true, indirect-api=false, port=PpDcmDataService_DID_StartApplication
        enable-take-address=true, indirect-api=false, port=PpDemDataService_DemDataElementClass_StartApplication
        enable-take-address=true, indirect-api=false, port=PpAliveWdgMSupervisedEntity_StartApplication
        enable-take-address=true, indirect-api=false, port=PpCsmKeyManagement_StartApplication_CsmKey
        enable-take-address=true, indirect-api=false, port=PpFreshnessManagement
        enable-take-address=false, indirect-api=false, port=PpRxLargeData
        enable-take-address=false, indirect-api=false, port=PpTxLargeData
        enable-take-address=true, indirect-api=false, port=PpStartApplication_CsmKey_MAC
        enable-take-address=true, indirect-api=false, port=PpStartApplication_CsmKey_Dec
        enable-take-address=true, indirect-api=false, port=PpStartApplication_CsmKey_Enc
        enable-take-address=true, indirect-api=false, port=PpStartApplication_MAC_Verify
        enable-take-address=true, indirect-api=false, port=PpStartApplication_MAC_Generate
        enable-take-address=true, indirect-api=false, port=PpStartApplication_ECB_AES_Decrypt
        enable-take-address=true, indirect-api=false, port=PpStartApplication_ECB_AES_Encrypt
        enable-take-address=true, indirect-api=false, port=PpTxCtrl
        enable-take-address=true, indirect-api=false, port=PpTxData
        enable-take-address=true, indirect-api=false, port=PpRxCtrl
        enable-take-address=true, indirect-api=false, port=PpRxData
        enable-take-address=true, indirect-api=false, port=PpSignal_StartAppl_TxData_MyECU_omsg_StartAppl_Tx_MyECU_oCAN_8c58228b_Tx
        enable-take-address=true, indirect-api=false, port=PpSignal_StartAppl_RxData_MyECU_omsg_StartAppl_Rx_MyECU_oCAN_315f9453_Rx
        enable-take-address=false, indirect-api=false, port=PpMasterCoreData1
        enable-take-address=false, indirect-api=false, port=PpSlaveCoreData1
        enable-take-address=false, indirect-api=false, port=PpRxEthernetCommunication
        enable-take-address=false, indirect-api=false, port=PpTxEthernetCommunication
      18 x runnable:
        StartApplication_Cyclic1ms
        StartApplication_Cyclic10ms
          sync call OpServerCallStartApplication_Cyclic10ms_CheckpointReached_PpAliveWdgMSupervisedEntity_StartApplication: operation=PpAliveWdgMSupervisedEntity_StartApplication.CheckpointReached, timeout=0
        StartApplication_Cyclic250ms
          data-receive-point-by-arguments:
            4 x access:
              DataReceivePointStartApplication_Cyclic250ms_PpSignal_MyECU_SecOC_Rx1_omsg_SecOC_MyECU_Rx_oCAN_985386a6_Rx_DeSignal_MyE_29951f13: accessed-variable=PpSignal_MyECU_SecOC_Rx1_omsg_SecOC_MyECU_Rx_oCAN_985386a6_Rx.DeSignal_MyECU_SecOC_Rx1_omsg_SecOC_MyECU_Rx_oCAN_985386a6_Rx
              DataReceivePointStartApplication_Cyclic250ms_PpSig_StartAppl_LinData_Rx_oFrame_LinTr_Slave1_oLIN00_149fe319_Rx_DeSig_St_2ce70d41: accessed-variable=PpSig_StartAppl_LinData_Rx_oFrame_LinTr_Slave1_oLIN00_149fe319_Rx.DeSig_StartAppl_LinData_Rx_oFrame_LinTr_Slave1_oLIN00_149fe319_Rx
              DataReceivePointStartApplication_Cyclic250ms_PpRxData_DeGeneric: accessed-variable=PpRxData.DeGeneric
              DataReceivePointStartApplication_Cyclic250ms_PpSignal_StartAppl_RxData_MyECU_omsg_StartAppl_Rx_MyECU_oCAN_315f9453_Rx_D_e2b22488: accessed-variable=PpSignal_StartAppl_RxData_MyECU_omsg_StartAppl_Rx_MyECU_oCAN_315f9453_Rx.DeSignal_StartAppl_RxData_MyECU_omsg_StartAppl_Rx_MyECU_oCAN_315f9453_Rx
          data-send-points:
            5 x access:
              DataSendPointStartApplication_Cyclic250ms_PpSig_StartAppl_LinData_Tx_oFrame_LinTr_MyECU_oLIN00_d383dc6b_Tx_DeSig_StartA_04398d4d: accessed-variable=PpSig_StartAppl_LinData_Tx_oFrame_LinTr_MyECU_oLIN00_d383dc6b_Tx.DeSig_StartAppl_LinData_Tx_oFrame_LinTr_MyECU_oLIN00_d383dc6b_Tx
              DataSendPointStartApplication_Cyclic250ms_PpSignal_MyECU_SecOC_Tx1_omsg_SecOC_MyECU_Tx_oCAN_fe3fbdd2_Tx_DeSignal_MyECU_3ff6f516: accessed-variable=PpSignal_MyECU_SecOC_Tx1_omsg_SecOC_MyECU_Tx_oCAN_fe3fbdd2_Tx.DeSignal_MyECU_SecOC_Tx1_omsg_SecOC_MyECU_Tx_oCAN_fe3fbdd2_Tx
              DataSendPointStartApplication_Cyclic250ms_PpTxCtrl_DeGeneric: accessed-variable=PpTxCtrl.DeGeneric
              DataSendPointStartApplication_Cyclic250ms_PpTxData_DeGeneric: accessed-variable=PpTxData.DeGeneric
              DataSendPointStartApplication_Cyclic250ms_PpSignal_StartAppl_TxData_MyECU_omsg_StartAppl_Tx_MyECU_oCAN_8c58228b_Tx_DeSi_19a5c978: accessed-variable=PpSignal_StartAppl_TxData_MyECU_omsg_StartAppl_Tx_MyECU_oCAN_8c58228b_Tx.DeSignal_StartAppl_TxData_MyECU_omsg_StartAppl_Tx_MyECU_oCAN_8c58228b_Tx
          read-local-variables:
            access StartApplication_Cyclic250ms_IrvOccuranceCounterDid_DIRECT_READ: accessed-variable=IrvOccuranceCounterDid
          10 x sync call, all with timeout=0:
            OpServerCallStartApplication_Cyclic250ms_GetCurrentComMode_UR_CN_LIN00_0a7bdc9c: operation=UR_CN_LIN00_0a7bdc9c.GetCurrentComMode
            OpServerCallStartApplication_Cyclic250ms_RequestComMode_UR_CN_LIN00_0a7bdc9c: operation=UR_CN_LIN00_0a7bdc9c.RequestComMode
            OpServerCallStartApplication_Cyclic250ms_GetCurrentComMode_UR_CN_CAN_52ce3533: operation=UR_CN_CAN_52ce3533.GetCurrentComMode
            OpServerCallStartApplication_Cyclic250ms_RequestComMode_UR_CN_CAN_52ce3533: operation=UR_CN_CAN_52ce3533.RequestComMode
            OpServerCallStartApplication_Cyclic250ms_GetCurrentComMode_UR_MyECU_EEI_V10_NM_507fc7ae: operation=UR_MyECU_EEI_V10_NM_507fc7ae.GetCurrentComMode
            OpServerCallStartApplication_Cyclic250ms_RequestComMode_UR_MyECU_EEI_V10_NM_507fc7ae: operation=UR_MyECU_EEI_V10_NM_507fc7ae.RequestComMode
            OpServerCallStartApplication_Cyclic250ms_GetCurrentComMode_UR_MyECU_EEI_U_2cc5e3dc: operation=UR_MyECU_EEI_U_2cc5e3dc.GetCurrentComMode
            OpServerCallStartApplication_Cyclic250ms_RequestComMode_UR_MyECU_EEI_U_2cc5e3dc: operation=UR_MyECU_EEI_U_2cc5e3dc.RequestComMode
            OpServerCallStartApplication_Cyclic250ms_ReadBlock_PpPS_StartApplication_NvMBlock1: operation=PpPS_StartApplication_NvMBlock1.ReadBlock
            OpServerCallStartApplication_Cyclic250ms_ReadBlock_PpPS_StartApplication_NvMBlock2: operation=PpPS_StartApplication_NvMBlock2.ReadBlock
        StartApplication_Cyclic1000ms
        StartApplication_Init: can-be-invoked-concurrently=true
          6 x sync call, all with timeout=0:
            OpServerCallStartApplication_Init_RequestComMode_UR_CN_LIN00_0a7bdc9c: operation=UR_CN_LIN00_0a7bdc9c.RequestComMode
            OpServerCallStartApplication_Init_RequestComMode_UR_CN_CAN_52ce3533: operation=UR_CN_CAN_52ce3533.RequestComMode
            OpServerCallStartApplication_Init_RequestComMode_UR_MyECU_EEI_V10_NM_507fc7ae: operation=UR_MyECU_EEI_V10_NM_507fc7ae.RequestComMode
            OpServerCallStartApplication_Init_RequestComMode_UR_MyECU_EEI_U_2cc5e3dc: operation=UR_MyECU_EEI_U_2cc5e3dc.RequestComMode
            OpServerCallStartApplication_Init_KeyElementSet_PpCsmKeyManagement_StartApplication_CsmKey: operation=PpCsmKeyManagement_StartApplication_CsmKey.KeyElementSet
            OpServerCallStartApplication_Init_KeySetValid_PpCsmKeyManagement_StartApplication_CsmKey: operation=PpCsmKeyManagement_StartApplication_CsmKey.KeySetValid
        StartApplication_OnDataRec_RxCtrl
          data-receive-point-by-arguments:
            access DataReceivePointStartApplication_OnDataRec_RxCtrl_PpRxCtrl_DeGeneric: accessed-variable=PpRxCtrl.DeGeneric
          data-send-points:
            access DataSendPointStartApplication_OnDataRec_RxCtrl_PpTxCtrl_DeGeneric: accessed-variable=PpTxCtrl.DeGeneric
          sync call OpServerCallStartApplication_OnDataRec_RxCtrl_SetOperationCycleState_PpDemOpCycle_PowerCycle: operation=PpDemOpCycle_PowerCycle.SetOperationCycleState, timeout=0
        StartApplication_OnDataRec_RxData
          data-receive-point-by-arguments:
            access DataReceivePointStartApplication_OnDataRec_RxData_PpRxData_DeGeneric: accessed-variable=PpRxData.DeGeneric
          data-send-points:
            access DataSendPointStartApplication_OnDataRec_RxData_PpTxCtrl_DeGeneric: accessed-variable=PpTxCtrl.DeGeneric
            access DataSendPointStartApplication_OnDataRec_RxData_PpMasterCoreData1_DeInterCoreMaster: accessed-variable=PpMasterCoreData1.DeInterCoreMaster
          read-local-variables:
            access StartApplication_OnDataRec_RxData_IrvOccuranceCounterDid_DIRECT_READ: accessed-variable=IrvOccuranceCounterDid
          sync call OpServerCallStartApplication_OnDataRec_RxData_WriteBlock_PpPS_StartApplication_NvMBlock1: operation=PpPS_StartApplication_NvMBlock1.WriteBlock, timeout=0
          sync call OpServerCallStartApplication_OnDataRec_RxData_WriteBlock_PpPS_StartApplication_NvMBlock2: operation=PpPS_StartApplication_NvMBlock2.WriteBlock, timeout=0
          sync call OpServerCallStartApplication_OnDataRec_RxData_SetEventStatus_PpDiagnosticMonitor_DEM_EVENT_StartApplication: operation=PpDiagnosticMonitor_DEM_EVENT_StartApplication.SetEventStatus, timeout=0
          written-local-variables:
            access StartApplication_OnDataRec_RxData_IrvOccuranceCounterDid_DIRECT_WRITE: accessed-variable=IrvOccuranceCounterDid
        StartApplication_MEM_JobFinished_StartApplication_NvMBlock1: can-be-invoked-concurrently=true
          data-send-points:
            access DataSendPointStartApplication_MEM_JobFinished_StartApplication_NvMBlock1_PpTxCtrl_DeGeneric: accessed-variable=PpTxCtrl.DeGeneric
            access DataSendPointStartApplication_MEM_JobFinished_StartApplication_NvMBlock1_PpTxData_DeGeneric: accessed-variable=PpTxData.DeGeneric
        StartApplication_MEM_JobFinished_StartApplication_NvMBlock2: can-be-invoked-concurrently=true
          data-send-points:
            access DataSendPointStartApplication_MEM_JobFinished_StartApplication_NvMBlock2_PpTxCtrl_DeGeneric: accessed-variable=PpTxCtrl.DeGeneric
            access DataSendPointStartApplication_MEM_JobFinished_StartApplication_NvMBlock2_PpTxData_DeGeneric: accessed-variable=PpTxData.DeGeneric
        StartApplication_DIAG_DcmReadData: can-be-invoked-concurrently=true
          read-local-variables:
            access StartApplication_DIAG_DcmReadData_IrvOccuranceCounterDid_DIRECT_READ: accessed-variable=IrvOccuranceCounterDid
        StartApplication_DIAG_DcmWriteData: can-be-invoked-concurrently=true
          written-local-variables:
            access StartApplication_DIAG_DcmWriteData_IrvOccuranceCounterDid_DIRECT_WRITE: accessed-variable=IrvOccuranceCounterDid
        StartApplication_DIAG_ConditionCheckRead: can-be-invoked-concurrently=true
        StartApplication_DIAG_DemReadData: can-be-invoked-concurrently=true
          read-local-variables:
            access StartApplication_DIAG_DemReadData_IrvOccuranceCounterDid_DIRECT_READ: accessed-variable=IrvOccuranceCounterDid
        StartApplication_SecOC_FreshnessManagement_GetRxFreshness
        StartApplication_SecOC_FreshnessManagement_GetTxFreshness
        StartApplication_OnDataRec_RxLargeData
          data-receive-point-by-arguments:
            access DataReceivePointStartApplication_OnDataRec_RxLargeData_PpRxLargeData_DeLargeDataControlCommunication: accessed-variable=PpRxLargeData.DeLargeDataControlCommunication
          data-send-points:
            access DataSendPointStartApplication_OnDataRec_RxLargeData_PpTxLargeData_DeLargeDataControlCommunication: accessed-variable=PpTxLargeData.DeLargeDataControlCommunication
          13 x sync call, all with timeout=0:
            OpServerCallStartApplication_OnDataRec_RxLargeData_Decrypt_PpStartApplication_ECB_AES_Decrypt: operation=PpStartApplication_ECB_AES_Decrypt.Decrypt
            OpServerCallStartApplication_OnDataRec_RxLargeData_Encrypt_PpStartApplication_ECB_AES_Encrypt: operation=PpStartApplication_ECB_AES_Encrypt.Encrypt
            OpServerCallStartApplication_OnDataRec_RxLargeData_MacGenerate_PpStartApplication_MAC_Generate: operation=PpStartApplication_MAC_Generate.MacGenerate
            OpServerCallStartApplication_OnDataRec_RxLargeData_MacVerify_PpStartApplication_MAC_Verify: operation=PpStartApplication_MAC_Verify.MacVerify
            OpServerCallStartApplication_OnDataRec_RxLargeData_KeySetValid_PpStartApplication_CsmKey_Enc: operation=PpStartApplication_CsmKey_Enc.KeySetValid
            OpServerCallStartApplication_OnDataRec_RxLargeData_KeyElementSet_PpStartApplication_CsmKey_Enc: operation=PpStartApplication_CsmKey_Enc.KeyElementSet
            OpServerCallStartApplication_OnDataRec_RxLargeData_KeyElementGet_PpStartApplication_CsmKey_Enc: operation=PpStartApplication_CsmKey_Enc.KeyElementGet
            OpServerCallStartApplication_OnDataRec_RxLargeData_KeySetValid_PpStartApplication_CsmKey_Dec: operation=PpStartApplication_CsmKey_Dec.KeySetValid
            OpServerCallStartApplication_OnDataRec_RxLargeData_KeyElementSet_PpStartApplication_CsmKey_Dec: operation=PpStartApplication_CsmKey_Dec.KeyElementSet
            OpServerCallStartApplication_OnDataRec_RxLargeData_KeyElementGet_PpStartApplication_CsmKey_Dec: operation=PpStartApplication_CsmKey_Dec.KeyElementGet
            OpServerCallStartApplication_OnDataRec_RxLargeData_KeySetValid_PpStartApplication_CsmKey_MAC: operation=PpStartApplication_CsmKey_MAC.KeySetValid
            OpServerCallStartApplication_OnDataRec_RxLargeData_KeyElementSet_PpStartApplication_CsmKey_MAC: operation=PpStartApplication_CsmKey_MAC.KeyElementSet
            OpServerCallStartApplication_OnDataRec_RxLargeData_KeyElementGet_PpStartApplication_CsmKey_MAC: operation=PpStartApplication_CsmKey_MAC.KeyElementGet
        StartApplication_OnDataRec_SlaveCore1: can-be-invoked-concurrently=true
          data-receive-point-by-arguments:
            access DataReceivePointStartApplication_OnDataRec_SlaveCore1_PpSlaveCoreData1_DeInterCoreSlave: accessed-variable=PpSlaveCoreData1.DeInterCoreSlave
        StartApplication_OnDataRec_EthernetCommunication
          data-receive-point-by-arguments:
            access DataReceivePointStartApplication_OnDataRec_EthernetCommunication_PpRxEthernetCommunication_DeEthernetCommunication: accessed-variable=PpRxEthernetCommunication.DeEthernetCommunication
          data-send-points:
            access DataSendPointStartApplication_OnDataRec_EthernetCommunication_PpTxEthernetCommunication_DeEthernetCommunication: accessed-variable=PpTxEthernetCommunication.DeEthernetCommunication
  swc implementation StartApplicationImplementation: programming-language=C, behavior=StartApplicationInternalBehavior
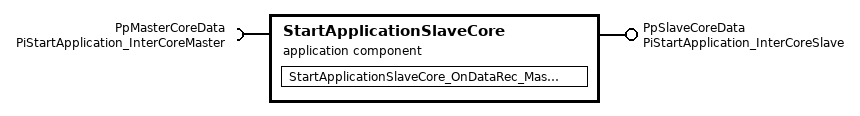
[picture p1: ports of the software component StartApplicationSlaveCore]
  application sw component type StartApplicationSlaveCore
    provide port PpSlaveCoreData: nonqueued-sender-com-spec{data-element=DeInterCoreSlave, init-value=fields=[0, 0]}, provided-interface=PiStartApplication_InterCoreSlave
    require port PpMasterCoreData: nonqueued-receiver-com-spec{data-element=DeInterCoreMaster, handle-out-of-range-status=SILENT, init-value=0}, required-interface=PiStartApplication_InterCoreMaster
    behavior StartApplicationSlaveCoreInternalBehavior: handle-termination-and-restart=NO-SUPPORT, supports-multiple-instantiation=true
      data received event DataReceivedEvent_StartApplicationSlaveCore_OnDataRec_MasterCore_PpMasterCoreData_DeInterCoreMaster: start-on-event=StartApplicationSlaveCore_OnDataRec_MasterCore, data=PpMasterCoreData.DeInterCoreMaster
      port-api-options:
        enable-take-address=false, indirect-api=false, port=PpSlaveCoreData
        enable-take-address=false, indirect-api=false, port=PpMasterCoreData
      runnable StartApplicationSlaveCore_OnDataRec_MasterCore: can-be-invoked-concurrently=true
        data-receive-point-by-arguments:
          access DataReceivePointStartApplicationSlaveCore_OnDataRec_MasterCore_PpMasterCoreData_DeInterCoreMaster: accessed-variable=PpMasterCoreData.DeInterCoreMaster
        data-send-points:
          access DataSendPointStartApplicationSlaveCore_OnDataRec_MasterCore_PpSlaveCoreData_DeInterCoreSlave: accessed-variable=PpSlaveCoreData.DeInterCoreSlave
  swc implementation StartApplicationSlaveCoreImplementation: programming-language=C, behavior=StartApplicationSlaveCoreInternalBehavior
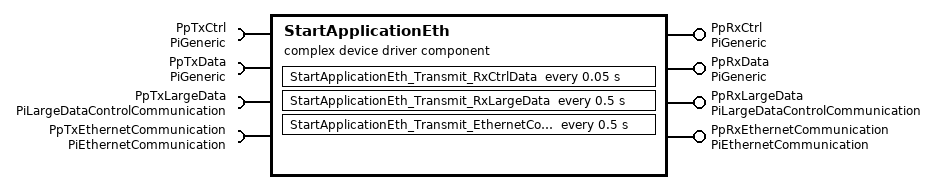
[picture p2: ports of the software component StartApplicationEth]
  complex device driver sw component type StartApplicationEth
    provide port PpRxCtrl: nonqueued-sender-com-spec{data-element=DeGeneric, init-value=0}, provided-interface=PiGeneric
    provide port PpRxData: nonqueued-sender-com-spec{data-element=DeGeneric, init-value=0}, provided-interface=PiGeneric
    require port PpTxCtrl: nonqueued-receiver-com-spec{data-element=DeGeneric, handle-out-of-range-status=SILENT, init-value=0}, required-interface=PiGeneric
    require port PpTxData: nonqueued-receiver-com-spec{data-element=DeGeneric, handle-out-of-range-status=SILENT, init-value=0}, required-interface=PiGeneric
    require port PpTxLargeData: nonqueued-receiver-com-spec{data-element=DeLargeDataControlCommunication, handle-out-of-range-status=SILENT}, required-interface=PiLargeDataControlCommunication
    provide port PpRxLargeData: nonqueued-sender-com-spec=DeLargeDataControlCommunication, provided-interface=PiLargeDataControlCommunication
    require port PpTxEthernetCommunication: nonqueued-receiver-com-spec{data-element=DeEthernetCommunication, handle-out-of-range-status=SILENT}, required-interface=PiEthernetCommunication
    provide port PpRxEthernetCommunication: nonqueued-sender-com-spec=DeEthernetCommunication, provided-interface=PiEthernetCommunication
    behavior StartApplicationEthInternalBehavior: handle-termination-and-restart=NO-SUPPORT
      4 x exclusive area:
        ExArReception
        ExArTransmission
        ExArReception_LargeData
        ExArReception_EthernetCommunication
      ar-typed-per-instance-memorys:
        7 x data:
          PimLastReceivedRxValue: type=EnumLastReceivedRxValueType
          PimRxCtrlSigValue: type=uint8
          PimRxDataSigValue: type=uint8
          PimTxCtrlSigValue: type=uint8
          PimTxDataSigValue: type=uint8
          PimRxLargeDataControlCommunicationInfo: type=IdtLargeDataControlCommunicationInfo
          PimRxEthernetCommunicationInfo: type=IdtEthernetCommunicationInfo
      init event Timer_StartApplicationEth_Init: start-on-event=StartApplicationEth_Init
      timing event Timer_StartApplicationEth_Transmit_RxCtrlData: start-on-event=StartApplicationEth_Transmit_RxCtrlData, period=0.05
      data received event DataReceivedEvent_StartApplicationEth_OnDataRec_TxData_PpTxData_DeGeneric: start-on-event=StartApplicationEth_OnDataRec_TxData, data=PpTxData.DeGeneric
      data received event DataReceivedEvent_StartApplicationEth_OnDataRec_TxCtrl_PpTxCtrl_DeGeneric: start-on-event=StartApplicationEth_OnDataRec_TxCtrl, data=PpTxCtrl.DeGeneric
      timing event Timer_StartApplicationEth_Transmit_RxLargeData: start-on-event=StartApplicationEth_Transmit_RxLargeData, period=0.5
      data received event DataReceivedEvent_StartApplicationEth_OnDataRec_TxLargeData_PpTxLargeData_DeLargeDataControlCommunication: start-on-event=StartApplicationEth_OnDataRec_TxLargeData, data=PpTxLargeData.DeLargeDataControlCommunication
      timing event Timer_StartApplicationEth_Transmit_EthernetCommunication: start-on-event=StartApplicationEth_Transmit_EthernetCommunication, period=0.5
      data received event DataReceivedEvent_StartApplicationEth_OnDataRec_EthernetCommunication_PpTxEthernetCommunication_DeEthernetCommunication: start-on-event=StartApplicationEth_OnDataRec_EthernetCommunication, data=PpTxEthernetCommunication.DeEthernetCommunication
      port-api-options:
        enable-take-address=true, indirect-api=false, port=PpRxCtrl
        enable-take-address=true, indirect-api=false, port=PpRxData
        enable-take-address=true, indirect-api=false, port=PpTxCtrl
        enable-take-address=true, indirect-api=false, port=PpTxData
        enable-take-address=false, indirect-api=false, port=PpTxLargeData
        enable-take-address=false, indirect-api=false, port=PpRxLargeData
        enable-take-address=false, indirect-api=false, port=PpTxEthernetCommunication
        enable-take-address=false, indirect-api=false, port=PpRxEthernetCommunication
      8 x runnable:
        StartApplicationEth_Init
        StartApplicationEth_Transmit_RxCtrlData: can-enter-exclusive-area=ExArReception
          data-send-points:
            access DataSendPointStartApplicationEth_Transmit_RxCtrlData_PpRxCtrl_DeGeneric: accessed-variable=PpRxCtrl.DeGeneric
            access DataSendPointStartApplicationEth_Transmit_RxCtrlData_PpRxData_DeGeneric: accessed-variable=PpRxData.DeGeneric
        StartApplicationEth_OnDataRec_TxData: can-enter-exclusive-area=ExArTransmission
          data-receive-point-by-arguments:
            access DataReceivePointStartApplicationEth_OnDataRec_TxData_PpTxData_DeGeneric: accessed-variable=PpTxData.DeGeneric
        StartApplicationEth_OnDataRec_TxCtrl: can-enter-exclusive-area=ExArTransmission
          data-receive-point-by-arguments:
            access DataReceivePointStartApplicationEth_OnDataRec_TxCtrl_PpTxCtrl_DeGeneric: accessed-variable=PpTxCtrl.DeGeneric
        StartApplicationEth_Transmit_RxLargeData: can-enter-exclusive-area=ExArReception_LargeData
          data-send-points:
            access DataSendPointStartApplicationEth_Transmit_RxLargeData_PpRxLargeData_DeLargeDataControlCommunication: accessed-variable=PpRxLargeData.DeLargeDataControlCommunication
        StartApplicationEth_OnDataRec_TxLargeData
          data-receive-point-by-arguments:
            access DataReceivePointStartApplicationEth_OnDataRec_TxLargeData_PpTxLargeData_DeLargeDataControlCommunication: accessed-variable=PpTxLargeData.DeLargeDataControlCommunication
        StartApplicationEth_Transmit_EthernetCommunication: can-enter-exclusive-area=ExArReception_EthernetCommunication
          data-send-points:
            access DataSendPointStartApplicationEth_Transmit_EthernetCommunication_PpRxEthernetCommunication_DeEthernetCommunication: accessed-variable=PpRxEthernetCommunication.DeEthernetCommunication
        StartApplicationEth_OnDataRec_EthernetCommunication
          data-receive-point-by-arguments:
            access DataReceivePointStartApplicationEth_OnDataRec_EthernetCommunication_PpTxEthernetCommunication_DeEthernetCommunication: accessed-variable=PpTxEthernetCommunication.DeEthernetCommunication
  swc implementation StartApplicationEthImplementation: programming-language=C, behavior=StartApplicationEthInternalBehavior
    resource consumption StartApplicationEthResourceConsumption
      5 x memory section:
        StartApplicationEth_START_SEC_CODE: sw-addrmethod=CODE, symbol=CODE
        StartApplicationEth_START_SEC_CONST_UNSPECIFIED: alignment=UNSPECIFIED, sw-addrmethod=CONST, symbol=CONST_UNSPECIFIED
        StartApplicationEth_START_SEC_VAR_NOINIT_UNSPECIFIED: alignment=UNSPECIFIED, sw-addrmethod=VAR_NO_INIT, symbol=VAR_NOINIT_UNSPECIFIED
        StartApplicationEth_START_SEC_VAR_INIT_UNSPECIFIED: alignment=UNSPECIFIED, sw-addrmethod=VAR_INIT, symbol=VAR_INIT_UNSPECIFIED
        StartApplicationEth_START_SEC_VAR_ZERO_INIT_UNSPECIFIED: alignment=UNSPECIFIED, sw-addrmethod=VAR_CLEARED, symbol=VAR_ZERO_INIT_UNSPECIFIED
